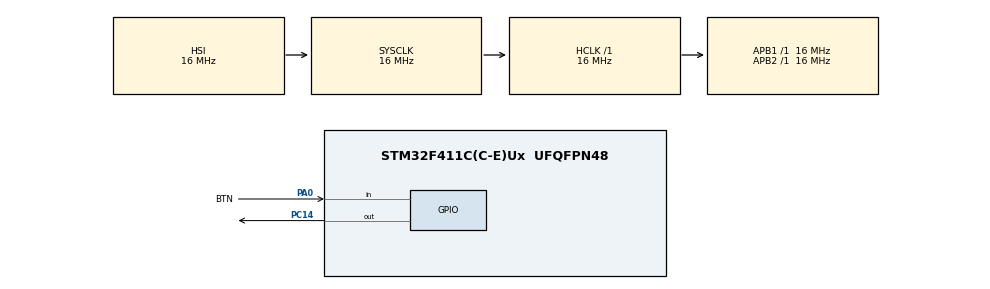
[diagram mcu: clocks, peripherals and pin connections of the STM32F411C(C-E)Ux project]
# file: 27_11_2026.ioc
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Mcu.Family=STM32F4
Mcu.Name=STM32F411C(C-E)Ux
Mcu.Package=UFQFPN48
NVIC.PriorityGroup=NVIC_PRIORITYGROUP_4
PA0-WKUP.GPIO_Label=BTN
PA0-WKUP.GPIO_PuPd=GPIO_PULLUP
PA0-WKUP.Signal=GPIO_Input
PA13.Mode=Serial_Wire
PA13.Signal=SYS_JTMS-SWDIO
PA14.Mode=Serial_Wire
PA14.Signal=SYS_JTCK-SWCLK
PC14-OSC32_IN.Signal=GPIO_Output
ProjectManager.HeapSize=0x200
ProjectManager.StackSize=0x400
ProjectManager.TargetToolchain=STM32CubeIDE
RCC.AHBFreq_Value=16000000
RCC.APB1Freq_Value=16000000
RCC.APB2Freq_Value=16000000
RCC.CortexFreq_Value=16000000
RCC.HSE_VALUE=25000000
RCC.HSI_VALUE=16000000
RCC.LSE_VALUE=32768
RCC.SYSCLKFreq_VALUE=16000000
RCC.VCOOutputFreq_Value=192000000
board=custom

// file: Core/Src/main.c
/* USER CODE BEGIN Header */
/**
  ******************************************************************************
  * @file           : main.c
  * @brief          : Main program body
  ******************************************************************************
  * @attention
  *
  * Copyright (c) 2026 STMicroelectronics.
  * All rights reserved.
  *
  * This software is licensed under terms that can be found in the LICENSE file
  * in the root directory of this software component.
  * If no LICENSE file comes with this software, it is provided AS-IS.
  *
  ******************************************************************************
  */
/* USER CODE END Header */
#include "main.h"

/* USER CODE BEGIN PV */
volatile uint32_t blink_tick_ms = 0U;

static const uint32_t periods[5] = {100U, 250U, 500U, 1000U, 2000U};
static uint32_t idx = 0U;
static volatile uint32_t press_cnt = 0U;
static uint32_t last_toggle = 0U;
static uint32_t now = 0U;
static uint32_t last_scan = 0U;
static uint32_t state = 0U;
static uint32_t prev_state = 0U;
static uint32_t period_ms = 0U;

/* USER CODE END PV */

void SystemClock_Config(void);
static void MX_GPIO_Init(void);

int main(void)
{

  /* MCU Configuration--------------------------------------------------------*/

  /* Reset of all peripherals, Initializes the Flash interface and the Systick. */
  HAL_Init();

  /* Configure the system clock */
  SystemClock_Config();

  /* Initialize all configured peripherals */
  MX_GPIO_Init();
  /* USER CODE BEGIN 2 */
  period_ms = periods[idx];
  last_toggle = blink_tick_ms;
  last_scan = last_toggle;

  /* USER CODE END 2 */

  /* Infinite loop */
  while (1)
  {

    /* USER CODE BEGIN 3 */
    now = blink_tick_ms;

    if ((now - last_toggle) >= period_ms)
    {
      last_toggle = now;
      GPIOC->ODR ^= GPIO_ODR_OD14;
    }

    if ((now - last_scan) >= 20U)
    {
      last_scan = now;
      state = ((GPIOA->IDR & GPIO_IDR_ID0) == 0U);

      if (state && !prev_state)
      {
        press_cnt++;
        idx = (idx + 1U) % 5U;
        period_ms = periods[idx];
      }

      prev_state = state;
    }
  }
  /* USER CODE END 3 */
}

void SystemClock_Config(void)
{
  RCC_OscInitTypeDef RCC_OscInitStruct = {0};
  RCC_ClkInitTypeDef RCC_ClkInitStruct = {0};

  /** Configure the main internal regulator output voltage
  */
  __HAL_RCC_PWR_CLK_ENABLE();
  __HAL_PWR_VOLTAGESCALING_CONFIG(PWR_REGULATOR_VOLTAGE_SCALE1);

  /** Initializes the RCC Oscillators according to the specified parameters
  * in the RCC_OscInitTypeDef structure.
  */
  RCC_OscInitStruct.OscillatorType = RCC_OSCILLATORTYPE_HSI;
  RCC_OscInitStruct.HSIState = RCC_HSI_ON;
  RCC_OscInitStruct.HSICalibrationValue = RCC_HSICALIBRATION_DEFAULT;
  RCC_OscInitStruct.PLL.PLLState = RCC_PLL_NONE;
  if (HAL_RCC_OscConfig(&RCC_OscInitStruct) != HAL_OK)
  {
    Error_Handler();
  }

  /** Initializes the CPU, AHB and APB buses clocks
  */
  RCC_ClkInitStruct.ClockType = RCC_CLOCKTYPE_HCLK|RCC_CLOCKTYPE_SYSCLK
                              |RCC_CLOCKTYPE_PCLK1|RCC_CLOCKTYPE_PCLK2;
  RCC_ClkInitStruct.SYSCLKSource = RCC_SYSCLKSOURCE_HSI;
  RCC_ClkInitStruct.AHBCLKDivider = RCC_SYSCLK_DIV1;
  RCC_ClkInitStruct.APB1CLKDivider = RCC_HCLK_DIV1;
  RCC_ClkInitStruct.APB2CLKDivider = RCC_HCLK_DIV1;

  if (HAL_RCC_ClockConfig(&RCC_ClkInitStruct, FLASH_LATENCY_0) != HAL_OK)
  {
    Error_Handler();
  }
}

static void MX_GPIO_Init(void)
{
  GPIO_InitTypeDef GPIO_InitStruct = {0};

  /* GPIO Ports Clock Enable */
  __HAL_RCC_GPIOC_CLK_ENABLE();
  __HAL_RCC_GPIOA_CLK_ENABLE();

  /*Configure GPIO pin Output Level */
  HAL_GPIO_WritePin(GPIOC, GPIO_PIN_14, GPIO_PIN_RESET);

  /*Configure GPIO pin : PC14 */
  GPIO_InitStruct.Pin = GPIO_PIN_14;
  GPIO_InitStruct.Mode = GPIO_MODE_OUTPUT_PP;
  GPIO_InitStruct.Pull = GPIO_NOPULL;
  GPIO_InitStruct.Speed = GPIO_SPEED_FREQ_LOW;
  HAL_GPIO_Init(GPIOC, &GPIO_InitStruct);

  /*Configure GPIO pin : BTN_Pin */
  GPIO_InitStruct.Pin = BTN_Pin;
  GPIO_InitStruct.Mode = GPIO_MODE_INPUT;
  GPIO_InitStruct.Pull = GPIO_PULLUP;
  HAL_GPIO_Init(BTN_GPIO_Port, &GPIO_InitStruct);

}

void Error_Handler(void)
{
  __disable_irq();
  while (1)
  {
  }
}
